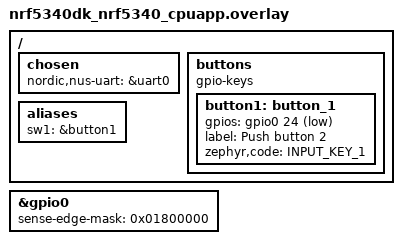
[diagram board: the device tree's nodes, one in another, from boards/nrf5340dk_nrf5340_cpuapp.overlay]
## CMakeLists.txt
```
#
# Copyright (c) 2018 Nordic Semiconductor
#
# SPDX-License-Identifier: LicenseRef-Nordic-5-Clause
#
cmake_minimum_required(VERSION 3.20.0)

find_package(Zephyr REQUIRED HINTS $ENV{ZEPHYR_BASE})
project(Blog_Power_300)

# NORDIC SDK APP START
target_sources(app PRIVATE
  src/main.c
)

# NORDIC SDK APP END
```

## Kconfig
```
#
# Copyright (c) 2018 Nordic Semiconductor
#
# SPDX-License-Identifier: LicenseRef-Nordic-5-Clause
#

source "Kconfig.zephyr"

menu "Nordic UART BLE GATT service sample"

config BT_NUS_THREAD_STACK_SIZE
	int "Thread stack size"
	default 1024
	help
	  Stack size used in each of the two threads

config BT_NUS_UART_BUFFER_SIZE
	int "UART payload buffer element size"
	default 40
	help
	  Size of the payload buffer in each RX and TX FIFO element

config BT_NUS_UART_RX_WAIT_TIME
	int "Timeout for UART RX complete event"
	default 50000
	help
	  Wait for RX complete event time in microseconds

config SETTINGS
	default y

config ZMS
	default y if (SOC_FLASH_NRF_RRAM || SOC_FLASH_NRF_MRAM)

config NVS
	default y if !(SOC_FLASH_NRF_RRAM || SOC_FLASH_NRF_MRAM)

config GPIO_WAKEUP_ENABLE
	bool "Use button to wake up device from system off"
	default y
	help
	  Enable system off wakeup from pressing sw0 button.

endmenu
```

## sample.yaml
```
sample:
  description: Bluetooth Low Energy UART service sample with Power optimization
  name: Bluetooth LE UART service
tests:
  sample.bluetooth.peripheral_uart:
    sysbuild: true
    build_only: true
    platform_allow:
      - nrf52dk/nrf52832
      - nrf52833dk/nrf52833
      - nrf52840dk/nrf52840
      - nrf5340dk/nrf5340/cpuapp
      - nrf5340dk/nrf5340/cpuapp/ns
      - thingy53/nrf5340/cpuapp
      - thingy53/nrf5340/cpuapp/ns
      - nrf21540dk/nrf52840
    integration_platforms:
      - nrf52dk/nrf52832
      - nrf52833dk/nrf52833
      - nrf52840dk/nrf52840
      - nrf5340dk/nrf5340/cpuapp
      - nrf5340dk/nrf5340/cpuapp/ns
      - thingy53/nrf5340/cpuapp
      - thingy53/nrf5340/cpuapp/ns
      - nrf21540dk/nrf52840
    tags:
      - bluetooth
      - ci_build
      - sysbuild
  sample.bluetooth.peripheral_uart_cdc:
    sysbuild: true
    build_only: true
    extra_args:
      - OVERLAY_CONFIG=prj_cdc.conf
      - DTC_OVERLAY_FILE="usb.overlay"
    integration_platforms:
      - nrf52840dk/nrf52840
      - nrf52833dk/nrf52833
    platform_allow:
      - nrf52840dk/nrf52840
      - nrf52833dk/nrf52833
    tags:
      - bluetooth
      - ci_build
      - sysbuild
  sample.bluetooth.peripheral_uart_minimal:
    sysbuild: true
    build_only: true
    extra_args: FILE_SUFFIX=minimal
    integration_platforms:
      - nrf52833dk/nrf52820
    platform_allow:
      - nrf52833dk/nrf52820
    tags:
      - bluetooth
      - ci_build
      - sysbuild
  sample.bluetooth.peripheral_uart_ble_rpc:
    sysbuild: true
    build_only: true
    extra_args:
      - SNIPPET=nordic-bt-rpc
      - FILE_SUFFIX=bt_rpc
    integration_platforms:
      - nrf5340dk/nrf5340/cpuapp
    platform_allow:
      - nrf5340dk/nrf5340/cpuapp
    tags:
      - bluetooth
      - ci_build
      - sysbuild
  sample.bluetooth.peripheral_uart.security_disabled:
    sysbuild: true
    build_only: true
    platform_allow:
      - nrf52dk/nrf52832
      - nrf52833dk/nrf52833
      - nrf52840dk/nrf52840
      - nrf5340dk/nrf5340/cpuapp
      - nrf5340dk/nrf5340/cpuapp/ns
      - thingy53/nrf5340/cpuapp
      - thingy53/nrf5340/cpuapp/ns
      - nrf21540dk/nrf52840
    integration_platforms:
      - nrf52840dk/nrf52840
    tags:
      - bluetooth
      - ci_build
      - sysbuild
    extra_configs:
      - CONFIG_BT_NUS_SECURITY_ENABLED=n
```

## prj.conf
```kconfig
#
# Copyright (c) 2018 Nordic Semiconductor
#
# SPDX-License-Identifier: LicenseRef-Nordic-5-Clause
#

# Enable the UART driver
CONFIG_UART_ASYNC_API=y 
CONFIG_NRFX_UARTE0=y
CONFIG_SERIAL=y

CONFIG_GPIO=y

# Make sure printk is printing to the UART console
CONFIG_CONSOLE=y
CONFIG_UART_CONSOLE=y

CONFIG_HEAP_MEM_POOL_SIZE=4096

CONFIG_BT=y
CONFIG_BT_PERIPHERAL=y
CONFIG_BT_DEVICE_NAME="Power_Blog_UART_Service"
CONFIG_BT_MAX_CONN=1
CONFIG_BT_MAX_PAIRED=1

# Enable the NUS service
CONFIG_BT_NUS=y

# Enable bonding
#CONFIG_BT_SETTINGS=y
#CONFIG_FLASH=y
#CONFIG_FLASH_PAGE_LAYOUT=y
#CONFIG_FLASH_MAP=y

# Enable DK LED and Buttons library
CONFIG_DK_LIBRARY=y

CONFIG_SYSTEM_WORKQUEUE_STACK_SIZE=2048
# Config logger ( disable rtt since i dont want DIF active)
CONFIG_LOG=n
CONFIG_USE_SEGGER_RTT=n
CONFIG_LOG_BACKEND_RTT=n
CONFIG_LOG_BACKEND_UART=n
CONFIG_LOG_PRINTK=n

CONFIG_ASSERT=y

# Power KCONFIG
CONFIG_PM_DEVICE=y
CONFIG_PM_DEVICE_RUNTIME=y
CONFIG_POWEROFF=y

#Use this Kconfig if you would like to use hwinfo_get_reset_cause()
CONFIG_HWINFO=y
```

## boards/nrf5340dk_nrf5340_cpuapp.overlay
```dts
/ {
	chosen {
		nordic,nus-uart = &uart0;
	};

		buttons {
		compatible = "gpio-keys";

		button1: button_1 {
			gpios = <&gpio0 24 (GPIO_PULL_UP | GPIO_ACTIVE_LOW)>;
			label = "Push button 2";
			//wakeup-source;
			zephyr,code = <INPUT_KEY_1>;
		};

	};

	/* These aliases are provided for compatibility with samples */
	aliases {
		sw1 = &button1;
	};

};

// sw0 p0.23
// sw1 p0.24
// sw2 p0.08
// sw3 p0.09
&gpio0 {
    sense-edge-mask = <0x01800000>; /* 1<<24 | 1 <<23 */
};
```

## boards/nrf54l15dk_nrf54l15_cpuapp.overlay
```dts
/ {
	cpuapp_sram@2002e000 {
		compatible = "zephyr,memory-region", "mmio-sram";
		reg = <0x2002e000 DT_SIZE_K(4)>;
		zephyr,memory-region = "RetainedMem";
		status = "okay";

		retainedmem0: retainedmem {
			compatible = "zephyr,retained-ram";
			status = "okay";
		};
	};

	aliases {
		retainedmemdevice = &retainedmem0;
	};
};

&cpuapp_sram {
	/* Shrink SRAM size to avoid overlap with retained memory region */
	reg = <0x20000000 DT_SIZE_K(184)>;
	ranges = <0x0 0x20000000 0x2e000>;
};

// sw0 p1.13 
// sw1 p1.09
// sw2 p1.08
// sw3 p0.04 /* Bit 4 set for pin 4 (Button 3) */
&gpio1 {
    sense-edge-mask = <0x00000200>; /* 1<<9 */
};
```

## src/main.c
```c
/*
 * Copyright (c) 2018 Nordic Semiconductor ASA
 *
 * SPDX-License-Identifier: LicenseRef-Nordic-5-Clause
 */

/** @file
 *  @brief Nordic UART Bridge Service (NUS) sample
 */
#include <uart_async_adapter.h>

#include <zephyr/types.h>
#include <zephyr/kernel.h>
#include <zephyr/drivers/uart.h>
#include <zephyr/usb/usb_device.h>

#include <zephyr/device.h>
#include <zephyr/devicetree.h>
#include <soc.h>

#include <zephyr/bluetooth/bluetooth.h>
#include <zephyr/bluetooth/uuid.h>
#include <zephyr/bluetooth/gatt.h>
#include <zephyr/bluetooth/hci.h>

#include <bluetooth/services/nus.h>

#include <hal/nrf_gpio.h>
#include <zephyr/drivers/gpio.h>
#include <zephyr/drivers/hwinfo.h>
#include <zephyr/pm/device.h>		//WRC Power Management
#include <zephyr/sys/poweroff.h>	//WRC System OFF
#include <zephyr/sys/util.h>

#include <zephyr/settings/settings.h>

#include <stdio.h>
#include <inttypes.h>
#include <string.h>

#include <zephyr/logging/log.h>

// use a gpio SW1 to wake from system OFF
#if defined(CONFIG_GPIO_WAKEUP_ENABLE)
static const struct gpio_dt_spec wake = GPIO_DT_SPEC_GET(DT_ALIAS(sw1), gpios);
#endif
//Set Button 1 (sw0) to put the device to sleep
static const struct gpio_dt_spec sleep = GPIO_DT_SPEC_GET_OR(DT_ALIAS(sw0), gpios, {0});
static struct gpio_callback button_cb_data;

#define WORQ_THREAD_STACK_SIZE 512
#define WQ_PRIO 4

// Define stack area used by workqueue thread
static K_THREAD_STACK_DEFINE(wq_stack_area, WORQ_THREAD_STACK_SIZE);

// Define queue structure for Sleep
static struct k_work_q sleep_work_q = {0};

struct work_info
{
    struct k_work_delayable work;
    uint8_t data[8];
} my_work;

#define LOG_MODULE_NAME peripheral_uart
LOG_MODULE_REGISTER(LOG_MODULE_NAME);

#define STACKSIZE CONFIG_BT_NUS_THREAD_STACK_SIZE
#define PRIORITY 7

#define DEVICE_NAME CONFIG_BT_DEVICE_NAME
#define DEVICE_NAME_LEN	(sizeof(DEVICE_NAME) - 1)

#define	WAITTIME			5000 		//Set a waititme between stages of the demo
#define KEY_POWER_OFF	   DK_BTN1_MSK	//BTN 1 (SW0) is used to put the device in SYSTEM OFF	

#define UART_BUF_SIZE CONFIG_BT_NUS_UART_BUFFER_SIZE
#define UART_WAIT_FOR_BUF_DELAY K_MSEC(50)
#define UART_WAIT_FOR_RX CONFIG_BT_NUS_UART_RX_WAIT_TIME

/*WRC set the advertising to a slow rate*/
#define BT_LE_ADV_CONN_SLOW BT_LE_ADV_PARAM(BT_LE_ADV_OPT_CONN, \
                                      0X0C80, \
                                       0X0F00, NULL)  

static K_SEM_DEFINE(ble_init_ok, 0, 1);

static struct bt_conn *current_conn;
static struct bt_conn *auth_conn;
static struct k_work adv_work;

static const struct device *uart = DEVICE_DT_GET(DT_CHOSEN(nordic_nus_uart));
static struct k_work_delayable uart_work;

struct uart_data_t {
	void *fifo_reserved;
	uint8_t data[UART_BUF_SIZE];
	uint16_t len;
};

static K_FIFO_DEFINE(fifo_uart_tx_data);
static K_FIFO_DEFINE(fifo_uart_rx_data);

static const struct bt_data ad[] = {
	BT_DATA_BYTES(BT_DATA_FLAGS, (BT_LE_AD_GENERAL | BT_LE_AD_NO_BREDR)),
	BT_DATA(BT_DATA_NAME_COMPLETE, DEVICE_NAME, DEVICE_NAME_LEN),
};

static const struct bt_data sd[] = {
	BT_DATA_BYTES(BT_DATA_UUID128_ALL, BT_UUID_NUS_VAL),
};

#ifdef CONFIG_UART_ASYNC_ADAPTER
UART_ASYNC_ADAPTER_INST_DEFINE(async_adapter);
#else
#define async_adapter NULL
#endif

static void uart_cb(const struct device *dev, struct uart_event *evt, void *user_data)
{
	ARG_UNUSED(dev);

	static size_t aborted_len;
	struct uart_data_t *buf;
	static uint8_t *aborted_buf;
	static bool disable_req;

	switch (evt->type) {
	case UART_TX_DONE:
		LOG_DBG("UART_TX_DONE");
		if ((evt->data.tx.len == 0) ||
		    (!evt->data.tx.buf)) {
			return;
		}

		if (aborted_buf) {
			buf = CONTAINER_OF(aborted_buf, struct uart_data_t,
					   data[0]);
			aborted_buf = NULL;
			aborted_len = 0;
		} else {
			buf = CONTAINER_OF(evt->data.tx.buf, struct uart_data_t,
					   data[0]);
		}

		k_free(buf);

		buf = k_fifo_get(&fifo_uart_tx_data, K_NO_WAIT);
		if (!buf) {
			return;
		}

		if (uart_tx(uart, buf->data, buf->len, SYS_FOREVER_MS)) {
			LOG_WRN("Failed to send data over UART");
		}

		break;

	case UART_RX_RDY:
		LOG_DBG("UART_RX_RDY");
		buf = CONTAINER_OF(evt->data.rx.buf, struct uart_data_t, data[0]);
		buf->len += evt->data.rx.len;

		if (disable_req) {
			return;
		}

		if ((evt->data.rx.buf[buf->len - 1] == '\n') ||
		    (evt->data.rx.buf[buf->len - 1] == '\r')) {
			disable_req = true;
			uart_rx_disable(uart);
		}

		break;

	case UART_RX_DISABLED:
		LOG_DBG("UART_RX_DISABLED");
		disable_req = false;

		buf = k_malloc(sizeof(*buf));
		if (buf) {
			buf->len = 0;
		} else {
			LOG_WRN("Not able to allocate UART receive buffer");
			k_work_reschedule(&uart_work, UART_WAIT_FOR_BUF_DELAY);
			return;
		}

		uart_rx_enable(uart, buf->data, sizeof(buf->data),
			       UART_WAIT_FOR_RX);

		break;

	case UART_RX_BUF_REQUEST:
		LOG_DBG("UART_RX_BUF_REQUEST");
		buf = k_malloc(sizeof(*buf));
		if (buf) {
			buf->len = 0;
			uart_rx_buf_rsp(uart, buf->data, sizeof(buf->data));
		} else {
			LOG_WRN("Not able to allocate UART receive buffer");
		}

		break;

	case UART_RX_BUF_RELEASED:
		LOG_DBG("UART_RX_BUF_RELEASED");
		buf = CONTAINER_OF(evt->data.rx_buf.buf, struct uart_data_t,
				   data[0]);

		if (buf->len > 0) {
			k_fifo_put(&fifo_uart_rx_data, buf);
		} else {
			k_free(buf);
		}

		break;

	case UART_TX_ABORTED:
		LOG_DBG("UART_TX_ABORTED");
		if (!aborted_buf) {
			aborted_buf = (uint8_t *)evt->data.tx.buf;
		}

		aborted_len += evt->data.tx.len;
		buf = CONTAINER_OF((void *)aborted_buf, struct uart_data_t,
				   data);

		uart_tx(uart, &buf->data[aborted_len],
			buf->len - aborted_len, SYS_FOREVER_MS);

		break;

	default:
		break;
	}
}

static void uart_work_handler(struct k_work *item)
{
	struct uart_data_t *buf;

	buf = k_malloc(sizeof(*buf));
	if (buf) {
		buf->len = 0;
	} else {
		LOG_WRN("Not able to allocate UART receive buffer");
		k_work_reschedule(&uart_work, UART_WAIT_FOR_BUF_DELAY);
		return;
	}

	uart_rx_enable(uart, buf->data, sizeof(buf->data), UART_WAIT_FOR_RX);
}

static bool uart_test_async_api(const struct device *dev)
{
	const struct uart_driver_api *api =
			(const struct uart_driver_api *)dev->api;

	return (api->callback_set != NULL);
}

static int uart_init(void)
{
	int err;
	int pos;
	struct uart_data_t *rx;
	struct uart_data_t *tx;

	if (!device_is_ready(uart)) {
		return -ENODEV;
	}

	if (IS_ENABLED(CONFIG_USB_DEVICE_STACK)) {
		err = usb_enable(NULL);
		if (err && (err != -EALREADY)) {
			LOG_ERR("Failed to enable USB");
			return err;
		}
	}

	rx = k_malloc(sizeof(*rx));
	if (rx) {
		rx->len = 0;
	} else {
		return -ENOMEM;
	}

	k_work_init_delayable(&uart_work, uart_work_handler);


	if (IS_ENABLED(CONFIG_UART_ASYNC_ADAPTER) && !uart_test_async_api(uart)) {
		/* Implement API adapter */
		uart_async_adapter_init(async_adapter, uart);
		uart = async_adapter;
	}

	err = uart_callback_set(uart, uart_cb, NULL);
	if (err) {
		k_free(rx);
		LOG_ERR("Cannot initialize UART callback");
		return err;
	}

	if (IS_ENABLED(CONFIG_UART_LINE_CTRL)) {
		LOG_INF("Wait for DTR");
		while (true) {
			uint32_t dtr = 0;

			uart_line_ctrl_get(uart, UART_LINE_CTRL_DTR, &dtr);
			if (dtr) {
				break;
			}
			/* Give CPU resources to low priority threads. */
			k_sleep(K_MSEC(100));
		}
		LOG_INF("DTR set");
		err = uart_line_ctrl_set(uart, UART_LINE_CTRL_DCD, 1);
		if (err) {
			LOG_WRN("Failed to set DCD, ret code %d", err);
		}
		err = uart_line_ctrl_set(uart, UART_LINE_CTRL_DSR, 1);
		if (err) {
			LOG_WRN("Failed to set DSR, ret code %d", err);
		}
	}

	tx = k_malloc(sizeof(*tx));

	if (tx) {
		pos = snprintf(tx->data, sizeof(tx->data),
			       "Starting NUS sample with Power Blog\r\n");

		if ((pos < 0) || (pos >= sizeof(tx->data))) {
			k_free(rx);
			k_free(tx);
			LOG_ERR("snprintf returned %d", pos);
			return -ENOMEM;
		}

		tx->len = pos;
	} else {
		k_free(rx);
		return -ENOMEM;
	}

	err = uart_tx(uart, tx->data, tx->len, SYS_FOREVER_MS);
	if (err) {
		k_free(rx);
		k_free(tx);
		LOG_ERR("Cannot display welcome message (err: %d)", err);
		return err;
	}

	err = uart_rx_enable(uart, rx->data, sizeof(rx->data), UART_WAIT_FOR_RX);
	if (err) {
		LOG_ERR("Cannot enable uart reception (err: %d)", err);
		/* Free the rx buffer only because the tx buffer will be handled in the callback */
		k_free(rx);
	}

	return err;
}

static void adv_work_handler(struct k_work *work)
{
	int err = bt_le_adv_start(BT_LE_ADV_CONN_SLOW, ad, ARRAY_SIZE(ad), sd, ARRAY_SIZE(sd));

	if (err) {
		LOG_ERR("Advertising failed to start (err %d)", err);
		return;
	}

	LOG_INF("Advertising successfully started");
}

static void advertising_start(void)
{
	k_work_submit(&adv_work);
}

static void connected(struct bt_conn *conn, uint8_t err)
{
	char addr[BT_ADDR_LE_STR_LEN];

	if (err) {
		LOG_ERR("Connection failed, err 0x%02x %s", err, bt_hci_err_to_str(err));
		return;
	}

	bt_addr_le_to_str(bt_conn_get_dst(conn), addr, sizeof(addr));
	LOG_INF("Connected %s", addr);

	current_conn = bt_conn_ref(conn);
}

static void disconnected(struct bt_conn *conn, uint8_t reason)
{
	char addr[BT_ADDR_LE_STR_LEN];

	bt_addr_le_to_str(bt_conn_get_dst(conn), addr, sizeof(addr));

	LOG_INF("Disconnected: %s, reason 0x%02x %s", addr, reason, bt_hci_err_to_str(reason));

	if (auth_conn) {
		bt_conn_unref(auth_conn);
		auth_conn = NULL;
	}

	if (current_conn) {
		bt_conn_unref(current_conn);
		current_conn = NULL;
	}
}

static void recycled_cb(void)
{
	LOG_INF("Connection object available from previous conn. Disconnect is complete!");
	advertising_start();
}

BT_CONN_CB_DEFINE(conn_callbacks) = {
	.connected        = connected,
	.disconnected     = disconnected,
	.recycled         = recycled_cb,
};


static void bt_receive_cb(struct bt_conn *conn, const uint8_t *const data,
			  uint16_t len)
{
	int err;
	char addr[BT_ADDR_LE_STR_LEN] = {0};

	bt_addr_le_to_str(bt_conn_get_dst(conn), addr, ARRAY_SIZE(addr));

	LOG_INF("Received data from: %s", addr);

	for (uint16_t pos = 0; pos != len;) {
		struct uart_data_t *tx = k_malloc(sizeof(*tx));

		if (!tx) {
			LOG_WRN("Not able to allocate UART send data buffer");
			return;
		}

		/* Keep the last byte of TX buffer for potential LF char. */
		size_t tx_data_size = sizeof(tx->data) - 1;

		if ((len - pos) > tx_data_size) {
			tx->len = tx_data_size;
		} else {
			tx->len = (len - pos);
		}

		memcpy(tx->data, &data[pos], tx->len);

		pos += tx->len;

		/* Append the LF character when the CR character triggered
		 * transmission from the peer.
		 */
		if ((pos == len) && (data[len - 1] == '\r')) {
			tx->data[tx->len] = '\n';
			tx->len++;
		}

		err = uart_tx(uart, tx->data, tx->len, SYS_FOREVER_MS);
		if (err) {
			k_fifo_put(&fifo_uart_tx_data, tx);
		}
	}
}

static struct bt_nus_cb nus_cb = {
	.received = bt_receive_cb,
};

void poweroff_work_handler(struct k_work *work_item)
{

#if defined(CONFIG_GPIO_WAKEUP_ENABLE)
	//After entering the system off by pressing SW0 you can wake on SW1
	/* configure sw1 as input, interrupt as level active to allow wake-up */

   // Configure pin sense for wakeup
    gpio_flags_t wflags = wake.dt_flags & GPIO_ACTIVE_LOW ? GPIO_PULL_UP : GPIO_PULL_DOWN;
    
    gpio_pin_configure_dt(&wake, GPIO_INPUT | wflags);
    gpio_add_callback(wake.port, &button_cb_data);
    nrf_gpio_cfg_sense_set(wake.pin, NRF_GPIO_PIN_SENSE_LOW);
	gpio_pin_configure_dt(&sleep, GPIO_DISCONNECTED);
    gpio_pin_interrupt_configure_dt(&sleep, GPIO_INT_DISABLE);
#endif

	hwinfo_clear_reset_cause();
	sys_poweroff();
}

void button_pressed(const struct device *dev, struct gpio_callback *cb, uint32_t pins)
{
    k_work_schedule_for_queue(&sleep_work_q, &my_work.work, K_MSEC(500));
}

static void configure_sleep_gpio(void)
{
	//Configure the Sleep Button
	gpio_flags_t sflags = sleep.dt_flags & GPIO_ACTIVE_LOW ? GPIO_PULL_UP : GPIO_PULL_DOWN;
    gpio_pin_configure_dt(&sleep, GPIO_INPUT | sflags);
    gpio_init_callback(&button_cb_data, button_pressed, BIT(sleep.pin) | BIT(wake.pin));
    gpio_add_callback(sleep.port, &button_cb_data);
    gpio_pin_interrupt_configure_dt(&sleep, GPIO_INT_EDGE_TO_ACTIVE);
	nrf_gpio_cfg_sense_set(sleep.pin, NRF_GPIO_PIN_SENSE_LOW);

}

int main(void)
{
	int err = 0;
	
	configure_sleep_gpio();

    k_work_init_delayable(&my_work.work, poweroff_work_handler);
    k_work_queue_start(&sleep_work_q, wq_stack_area, K_THREAD_STACK_SIZEOF(wq_stack_area), WQ_PRIO, NULL);

	err = uart_init();
	if (err) {
		LOG_ERR("Failed to initialize UART (err: %d)", err);
		return 0;
	}

	err = bt_enable(NULL);
	if (err) {
		LOG_ERR("Failed to initialize BT (err: %d)", err);
		return 0;

	}

	LOG_INF("Bluetooth initialized");

	k_sem_give(&ble_init_ok);

	if (IS_ENABLED(CONFIG_SETTINGS)) {
		settings_load();
	}

	err = bt_nus_init(&nus_cb);
	if (err) {
		LOG_ERR("Failed to initialize UART service (err: %d)", err);
		return 0;
	}

	k_work_init(&adv_work, adv_work_handler);
	advertising_start();
	//Added waititme just to see the device power level during advertising before we shut down the UART
	k_sleep(K_MSEC(WAITTIME));  

	//Suspend the UART to reduce power
	//You must call uart_rx_disable() and wait for the UART_RX_DISABLED event before calling 
	//pm_device_action_run(uart, PM_DEVICE_ACTION_SUSPEND). 
	//If you suspend the UART while RX is still enabled, it can cause assertion failures or crashes.
	// A simple workaround is to add a delay (e.g., k_sleep) after disabling RX,
	// but the correct approach is to wait for the callback/event indicating RX is disabled before suspending the device.
	err = uart_rx_disable(uart);
		__ASSERT(err == 0, "Failed to disable uart rx");

	err = pm_device_action_run(uart, PM_DEVICE_ACTION_SUSPEND);
	if (err < 0) {
		printf("Could not suspend console (%d)\n", err);
		return 0;
	}

	//Adding more waittime to see power levels of advertising with no UART.
	k_sleep(K_MSEC(WAITTIME));
	//Will shut down Advertising to see Idle power level
	bt_le_adv_stop();
	
	for (;;) {
	/* will put the current thread into a idle state forever. 
	The thread will not become runnable again unless it is explicitly woken up by another thread using k_wakeup()*/
		k_sleep(K_FOREVER);  
		}
}

void ble_write_thread(void)
{
	/* Don't go any further until BLE is initialized */
	k_sem_take(&ble_init_ok, K_FOREVER);
	struct uart_data_t nus_data = {
		.len = 0,
	};

	for (;;) {
		/* Wait indefinitely for data to be sent over bluetooth */
		struct uart_data_t *buf = k_fifo_get(&fifo_uart_rx_data,
						     K_FOREVER);

		int plen = MIN(sizeof(nus_data.data) - nus_data.len, buf->len);
		int loc = 0;

		while (plen > 0) {
			memcpy(&nus_data.data[nus_data.len], &buf->data[loc], plen);
			nus_data.len += plen;
			loc += plen;

			if (nus_data.len >= sizeof(nus_data.data) ||
			   (nus_data.data[nus_data.len - 1] == '\n') ||
			   (nus_data.data[nus_data.len - 1] == '\r')) {
				if (bt_nus_send(NULL, nus_data.data, nus_data.len)) {
					LOG_WRN("Failed to send data over BLE connection");
				}
				nus_data.len = 0;
			}

			plen = MIN(sizeof(nus_data.data), buf->len - loc);
		}

		k_free(buf);
	}
}

K_THREAD_DEFINE(ble_write_thread_id, STACKSIZE, ble_write_thread, NULL, NULL,
		NULL, PRIORITY, 0, 0);
```
